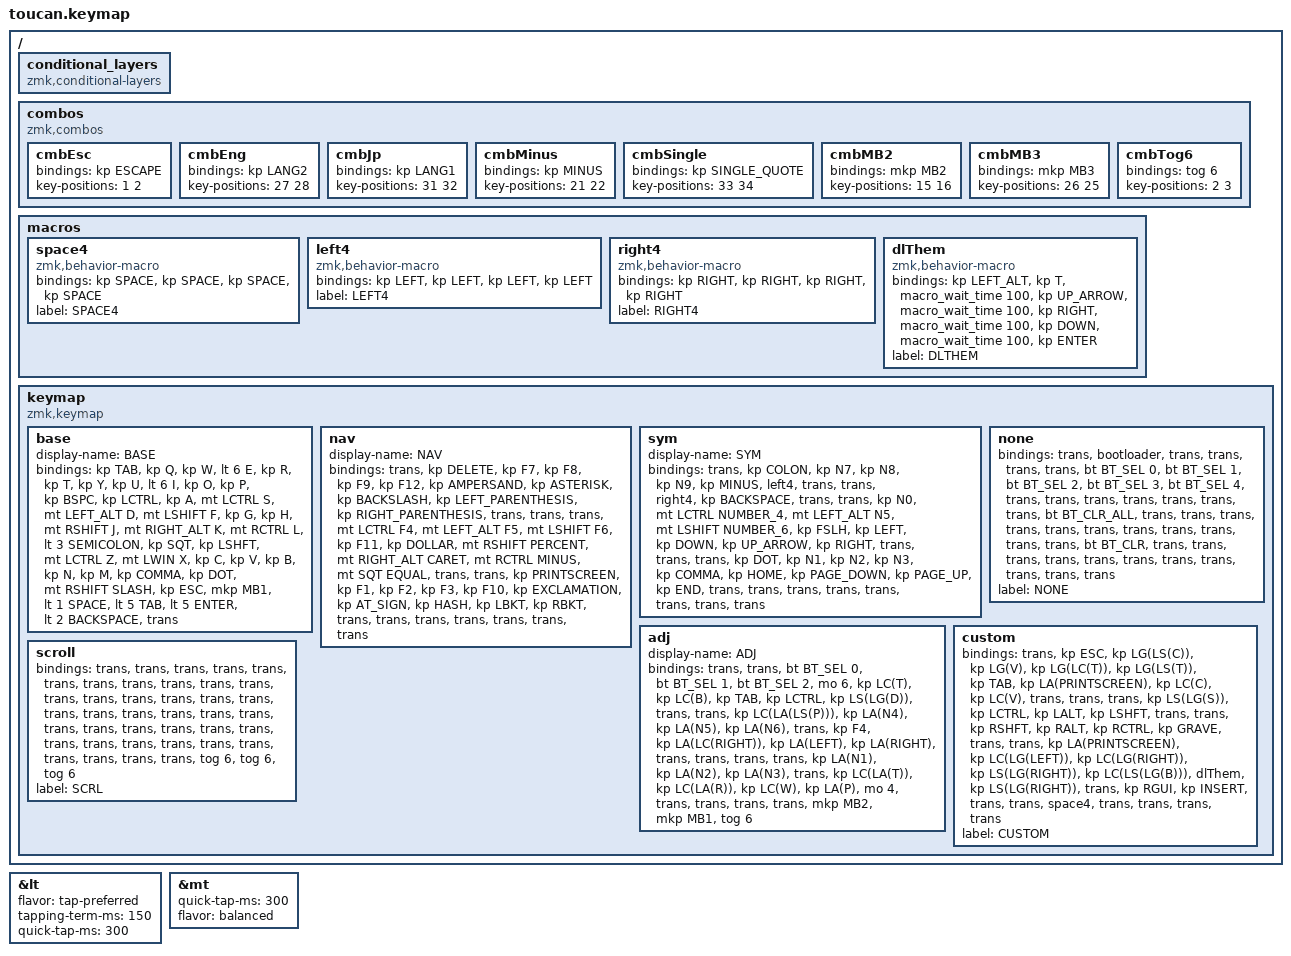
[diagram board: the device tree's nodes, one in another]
#include <behaviors.dtsi>
#include <dt-bindings/zmk/bt.h>
#include <dt-bindings/zmk/keys.h>
#include <dt-bindings/zmk/pointing.h>

#define BASE 0
#define NAV  1
#define SYM  2
#define ADJ  3

&lt {
    flavor = "tap-preferred";
    tapping-term-ms = <150>;
    quick-tap-ms = <300>;
};

&mt {
    quick-tap-ms = <300>;
    flavor = "balanced";
};

/ {
    conditional_layers { compatible = "zmk,conditional-layers"; };

    combos {
        compatible = "zmk,combos";

        cmbEsc {
            bindings = <&kp ESCAPE>;
            key-positions = <1 2>;
        };

        cmbEng {
            bindings = <&kp LANG2>;
            key-positions = <27 28>;
        };

        cmbJp {
            bindings = <&kp LANG1>;
            key-positions = <31 32>;
        };

        cmbMinus {
            bindings = <&kp MINUS>;
            key-positions = <21 22>;
        };

        cmbSingle {
            bindings = <&kp SINGLE_QUOTE>;
            key-positions = <33 34>;
        };

        cmbMB2 {
            bindings = <&mkp MB2>;
            key-positions = <15 16>;
        };

        cmbMB3 {
            bindings = <&mkp MB3>;
            key-positions = <26 25>;
        };

        cmbTog6 {
            bindings = <&tog 6>;
            key-positions = <2 3>;
        };
    };

    macros {
        space4: space4 {
            compatible = "zmk,behavior-macro";
            #binding-cells = <0>;
            bindings = <&kp SPACE &kp SPACE &kp SPACE &kp SPACE>;
            label = "SPACE4";
        };

        left4: left4 {
            compatible = "zmk,behavior-macro";
            #binding-cells = <0>;
            bindings = <&kp LEFT &kp LEFT &kp LEFT &kp LEFT>;
            label = "LEFT4";
        };

        right4: right4 {
            compatible = "zmk,behavior-macro";
            #binding-cells = <0>;
            bindings = <&kp RIGHT &kp RIGHT &kp RIGHT &kp RIGHT>;
            label = "RIGHT4";
        };

        dlThem: dlThem {
            compatible = "zmk,behavior-macro";
            #binding-cells = <0>;
            bindings =
                <&kp LEFT_ALT &kp T>,
                <&macro_wait_time 100>,
                <&kp UP_ARROW>,
                <&macro_wait_time 100>,
                <&kp RIGHT>,
                <&macro_wait_time 100>,
                <&kp DOWN>,
                <&macro_wait_time 100>,
                <&kp ENTER>;

            label = "DLTHEM";
        };
    };

    keymap {
        compatible = "zmk,keymap";

        base {
            display-name = "BASE";
            bindings = <
&kp TAB  &kp Q  &kp W  &lt 6 E  &kp R  &kp T  &kp Y  &kp U  &lt 6 I  &kp O  &kp P  &kp BSPC  &kp LCTRL  &kp A  &mt LCTRL S  &mt LEFT_ALT D  &mt LSHIFT F  &kp G  &kp H  &mt RSHIFT J  &mt RIGHT_ALT K  &mt RCTRL L  &lt 3 SEMICOLON  &kp SQT  &kp LSHFT  &mt LCTRL Z  &mt LWIN X  &kp C  &kp V  &kp B  &kp N  &kp M  &kp COMMA  &kp DOT  &mt RSHIFT SLASH  &kp ESC  &mkp MB1  &lt 1 SPACE  &lt 5 TAB  &lt 5 ENTER  &lt 2 BACKSPACE  &trans
            >;
        };

        nav {
            display-name = "NAV";
            bindings = <
&trans  &kp DELETE  &kp F7  &kp F8  &kp F9  &kp F12  &kp AMPERSAND  &kp ASTERISK  &kp BACKSLASH  &kp LEFT_PARENTHESIS  &kp RIGHT_PARENTHESIS  &trans  &trans  &trans  &mt LCTRL F4  &mt LEFT_ALT F5  &mt LSHIFT F6  &kp F11  &kp DOLLAR  &mt RSHIFT PERCENT  &mt RIGHT_ALT CARET  &mt RCTRL MINUS  &mt SQT EQUAL  &trans  &trans  &kp PRINTSCREEN  &kp F1  &kp F2  &kp F3  &kp F10  &kp EXCLAMATION  &kp AT_SIGN  &kp HASH  &kp LBKT  &kp RBKT  &trans  &trans  &trans  &trans  &trans  &trans  &trans
            >;
        };

        sym {
            display-name = "SYM";
            bindings = <
&trans  &kp COLON  &kp N7  &kp N8  &kp N9  &kp MINUS  &left4  &trans  &trans  &right4  &kp BACKSPACE  &trans  &trans  &kp N0  &mt LCTRL NUMBER_4  &mt LEFT_ALT N5  &mt LSHIFT NUMBER_6  &kp FSLH  &kp LEFT  &kp DOWN  &kp UP_ARROW  &kp RIGHT  &trans  &trans  &trans  &kp DOT  &kp N1  &kp N2  &kp N3  &kp COMMA  &kp HOME  &kp PAGE_DOWN  &kp PAGE_UP  &kp END  &trans  &trans  &trans  &trans  &trans  &trans  &trans  &trans
            >;
        };

        adj {
            display-name = "ADJ";
            bindings = <
&trans  &trans  &bt BT_SEL 0  &bt BT_SEL 1  &bt BT_SEL 2  &mo 6  &kp LC(T)  &kp LC(B)  &kp TAB  &kp LCTRL  &kp LS(LG(D))  &trans  &trans  &kp LC(LA(LS(P)))  &kp LA(N4)  &kp LA(N5)  &kp LA(N6)  &trans  &kp F4  &kp LA(LC(RIGHT))  &kp LA(LEFT)  &kp LA(RIGHT)  &trans  &trans  &trans  &trans  &kp LA(N1)  &kp LA(N2)  &kp LA(N3)  &trans  &kp LC(LA(T))  &kp LC(LA(R))  &kp LC(W)  &kp LA(P)  &mo 4  &trans  &trans  &trans  &trans  &mkp MB2  &mkp MB1  &tog 6
            >;
        };

        none {
            bindings = <
&trans  &bootloader  &trans  &trans  &trans  &trans  &bt BT_SEL 0  &bt BT_SEL 1  &bt BT_SEL 2  &bt BT_SEL 3  &bt BT_SEL 4  &trans  &trans  &trans  &trans  &trans  &trans  &trans  &bt BT_CLR_ALL  &trans  &trans  &trans  &trans  &trans  &trans  &trans  &trans  &trans  &trans  &trans  &bt BT_CLR  &trans  &trans  &trans  &trans  &trans  &trans  &trans  &trans  &trans  &trans  &trans
            >;

            label = "NONE";
        };

        custom {
            bindings = <
&trans  &kp ESC  &kp LG(LS(C))  &kp LG(V)  &kp LG(LC(T))  &kp LG(LS(T))  &kp TAB  &kp LA(PRINTSCREEN)  &kp LC(C)  &kp LC(V)  &trans  &trans  &trans  &kp LS(LG(S))  &kp LCTRL  &kp LALT  &kp LSHFT  &trans  &trans  &kp RSHFT  &kp RALT  &kp RCTRL  &kp GRAVE  &trans  &trans  &kp LA(PRINTSCREEN)  &kp LC(LG(LEFT))  &kp LC(LG(RIGHT))  &kp LS(LG(RIGHT))  &kp LC(LS(LG(B)))  &dlThem  &kp LS(LG(RIGHT))  &trans  &kp RGUI  &kp INSERT  &trans  &trans  &space4  &trans  &trans  &trans  &trans
            >;

            label = "CUSTOM";
        };

        scroll {
            bindings = <
&trans  &trans  &trans  &trans  &trans  &trans  &trans  &trans  &trans  &trans  &trans  &trans  &trans  &trans  &trans  &trans  &trans  &trans  &trans  &trans  &trans  &trans  &trans  &trans  &trans  &trans  &trans  &trans  &trans  &trans  &trans  &trans  &trans  &trans  &trans  &trans  &trans  &trans  &trans  &tog 6  &tog 6  &tog 6
            >;

            label = "SCRL";
        };
    };
};
